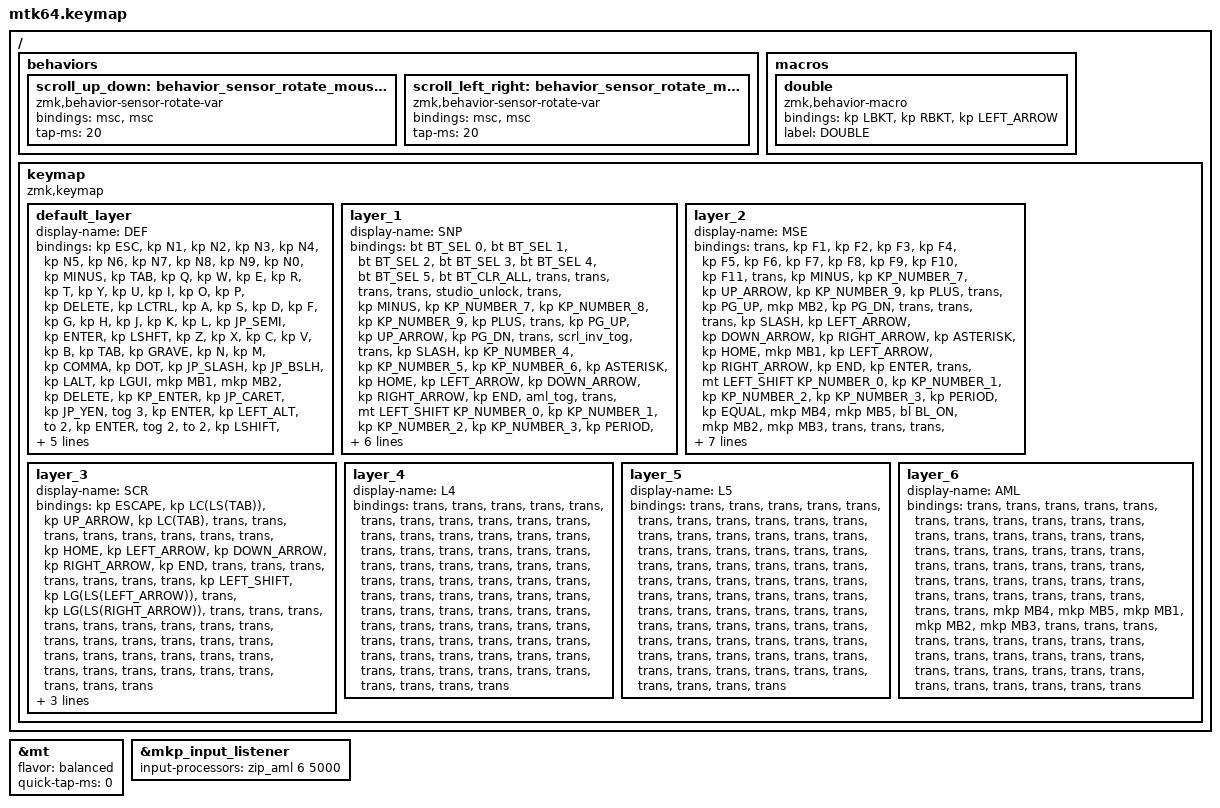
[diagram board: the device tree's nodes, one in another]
#include <input/processors.dtsi>
#include <behaviors.dtsi>
#include <dt-bindings/zmk/backlight.h>
#include <dt-bindings/zmk/bt.h>
#include <dt-bindings/zmk/keys.h>
#include <dt-bindings/zmk/pointing.h>
#include "keycode_japanese.h"

// スクロール量の設定

#define ZMK_POINTING_DEFAULT_SCRL_VAL 100

&mt {
    flavor = "balanced";
    quick-tap-ms = <0>;
};

&mkp_input_listener { input-processors = <&zip_aml 6 5000>; };

/ {
    behaviors {
        // 垂直スクロール用のbehaviorの設定

        scroll_up_down: behavior_sensor_rotate_mouse_wheel_up_down {
            compatible = "zmk,behavior-sensor-rotate-var";
            #sensor-binding-cells = <2>;
            bindings = <&msc>, <&msc>;

            tap-ms = <20>; // スクロールのタップ時間
        };

        // 水平スクロール用のbehaviorの設定

        scroll_left_right: behavior_sensor_rotate_mouse_wheel_left_right {
            compatible = "zmk,behavior-sensor-rotate-var";
            #sensor-binding-cells = <2>;
            bindings = <&msc>, <&msc>;

            tap-ms = <20>; // スクロールのタップ時間
        };
    };
};

/ {
    macros {
        double: double {
            compatible = "zmk,behavior-macro";
            #binding-cells = <0>;
            bindings = <&kp LBKT &kp RBKT &kp LEFT_ARROW>;
            label = "DOUBLE";
        };
    };

    keymap {
        compatible = "zmk,keymap";

        default_layer {
            display-name = "DEF";
            bindings = <
&kp ESC  &kp N1  &kp N2  &kp N3  &kp N4  &kp N5  &kp N6  &kp N7  &kp N8  &kp N9  &kp N0  &kp MINUS  &kp TAB  &kp Q  &kp W  &kp E  &kp R  &kp T  &kp Y  &kp U  &kp I  &kp O  &kp P  &kp DELETE  &kp LCTRL  &kp A  &kp S  &kp D  &kp F  &kp G  &kp H  &kp J  &kp K  &kp L  &kp JP_SEMI  &kp ENTER  &kp LSHFT  &kp Z  &kp X  &kp C  &kp V  &kp B  &kp TAB  &kp GRAVE  &kp N  &kp M  &kp COMMA  &kp DOT  &kp JP_SLASH  &kp JP_BSLH  &kp LALT  &kp LGUI  &mkp MB1  &mkp MB2  &kp DELETE  &kp KP_ENTER  &kp JP_CARET  &kp JP_YEN  &tog 3  &kp ENTER  &kp LEFT_ALT  &to 2  &kp ENTER  &tog 2  &to 2  &kp LSHIFT  &mo 1  &mo 2  &mo 3  &mo 1  &mo 2  &mo 3  &mo 1  &mo 2  &mo 3
            >;

            sensor-bindings = <
                &inc_dec_kp LEFT_ARROW RIGHT_ARROW
                &inc_dec_kp UP_ARROW   DOWN_ARROW
            >;
        };

        layer_1 {
            display-name = "SNP";
            bindings = <
&bt BT_SEL 0  &bt BT_SEL 1  &bt BT_SEL 2  &bt BT_SEL 3  &bt BT_SEL 4  &bt BT_SEL 5  &bt BT_CLR_ALL  &trans  &trans  &trans  &trans  &studio_unlock  &trans  &kp MINUS  &kp KP_NUMBER_7  &kp KP_NUMBER_8  &kp KP_NUMBER_9  &kp PLUS  &trans  &kp PG_UP  &kp UP_ARROW  &kp PG_DN  &trans  &scrl_inv_tog  &trans  &kp SLASH  &kp KP_NUMBER_4  &kp KP_NUMBER_5  &kp KP_NUMBER_6  &kp ASTERISK  &kp HOME  &kp LEFT_ARROW  &kp DOWN_ARROW  &kp RIGHT_ARROW  &kp END  &aml_tog  &trans  &mt LEFT_SHIFT KP_NUMBER_0  &kp KP_NUMBER_1  &kp KP_NUMBER_2  &kp KP_NUMBER_3  &kp PERIOD  &kp EQUAL  &mkp MB4  &mkp MB5  &bl BL_OFF  &mkp MB2  &mkp MB3  &trans  &cpi_inc  &trans  &trans  &trans  &trans  &trans  &trans  &trans  &cpi_dec  &trans  &trans  &trans  &trans  &trans  &trans  &trans  &trans  &trans  &trans  &trans  &trans  &trans  &trans  &trans  &trans  &trans
            >;
        };

        layer_2 {
            display-name = "MSE";
            bindings = <
&trans  &kp F1  &kp F2  &kp F3  &kp F4  &kp F5  &kp F6  &kp F7  &kp F8  &kp F9  &kp F10  &kp F11  &trans  &kp MINUS  &kp KP_NUMBER_7  &kp UP_ARROW  &kp KP_NUMBER_9  &kp PLUS  &trans  &kp PG_UP  &mkp MB2  &kp PG_DN  &trans  &trans  &trans  &kp SLASH  &kp LEFT_ARROW  &kp DOWN_ARROW  &kp RIGHT_ARROW  &kp ASTERISK  &kp HOME  &mkp MB1  &kp LEFT_ARROW  &kp RIGHT_ARROW  &kp END  &kp ENTER  &trans  &mt LEFT_SHIFT KP_NUMBER_0  &kp KP_NUMBER_1  &kp KP_NUMBER_2  &kp KP_NUMBER_3  &kp PERIOD  &kp EQUAL  &mkp MB4  &mkp MB5  &bl BL_ON  &mkp MB2  &mkp MB3  &trans  &trans  &trans  &trans  &trans  &trans  &mkp MB2  &mkp MB1  &trans  &trans  &trans  &trans  &trans  &to 0  &trans  &trans  &to 0  &trans  &trans  &trans  &trans  &trans  &trans  &trans  &trans  &trans  &trans
            >;

            sensor-bindings = <
                &inc_dec_kp TAB LS(TAB) 
                &inc_dec_kp PG_UP PG_DN
            >;
        };

        layer_3 {
            display-name = "SCR";
            bindings = <
&kp ESCAPE  &kp LC(LS(TAB))  &kp UP_ARROW  &kp LC(TAB)  &trans  &trans  &trans  &trans  &trans  &trans  &trans  &trans  &kp HOME  &kp LEFT_ARROW  &kp DOWN_ARROW  &kp RIGHT_ARROW  &kp END  &trans  &trans  &trans  &trans  &trans  &trans  &trans  &kp LEFT_SHIFT  &kp LG(LS(LEFT_ARROW))  &trans  &kp LG(LS(RIGHT_ARROW))  &trans  &trans  &trans  &trans  &trans  &trans  &trans  &trans  &trans  &trans  &trans  &trans  &trans  &trans  &trans  &trans  &trans  &trans  &trans  &trans  &trans  &trans  &trans  &trans  &trans  &trans  &trans  &trans  &trans  &trans
            >;

            sensor-bindings = <
                &scroll_left_right SCRL_LEFT SCRL_RIGHT
                &scroll_up_down SCRL_UP SCRL_DOWN
            >;
        };

        layer_4 {
            display-name = "L4";
            bindings = <
&trans  &trans  &trans  &trans  &trans  &trans  &trans  &trans  &trans  &trans  &trans  &trans  &trans  &trans  &trans  &trans  &trans  &trans  &trans  &trans  &trans  &trans  &trans  &trans  &trans  &trans  &trans  &trans  &trans  &trans  &trans  &trans  &trans  &trans  &trans  &trans  &trans  &trans  &trans  &trans  &trans  &trans  &trans  &trans  &trans  &trans  &trans  &trans  &trans  &trans  &trans  &trans  &trans  &trans  &trans  &trans  &trans  &trans  &trans  &trans  &trans  &trans  &trans  &trans  &trans  &trans  &trans  &trans  &trans  &trans  &trans  &trans  &trans  &trans  &trans
            >;
        };

        layer_5 {
            display-name = "L5";
            bindings = <
&trans  &trans  &trans  &trans  &trans  &trans  &trans  &trans  &trans  &trans  &trans  &trans  &trans  &trans  &trans  &trans  &trans  &trans  &trans  &trans  &trans  &trans  &trans  &trans  &trans  &trans  &trans  &trans  &trans  &trans  &trans  &trans  &trans  &trans  &trans  &trans  &trans  &trans  &trans  &trans  &trans  &trans  &trans  &trans  &trans  &trans  &trans  &trans  &trans  &trans  &trans  &trans  &trans  &trans  &trans  &trans  &trans  &trans  &trans  &trans  &trans  &trans  &trans  &trans  &trans  &trans  &trans  &trans  &trans  &trans  &trans  &trans  &trans  &trans  &trans
            >;
        };

        layer_6 {
            display-name = "AML";
            bindings = <
&trans  &trans  &trans  &trans  &trans  &trans  &trans  &trans  &trans  &trans  &trans  &trans  &trans  &trans  &trans  &trans  &trans  &trans  &trans  &trans  &trans  &trans  &trans  &trans  &trans  &trans  &trans  &trans  &trans  &trans  &trans  &trans  &trans  &trans  &trans  &trans  &trans  &trans  &trans  &trans  &trans  &trans  &trans  &mkp MB4  &mkp MB5  &mkp MB1  &mkp MB2  &mkp MB3  &trans  &trans  &trans  &trans  &trans  &trans  &trans  &trans  &trans  &trans  &trans  &trans  &trans  &trans  &trans  &trans  &trans  &trans  &trans  &trans  &trans  &trans  &trans  &trans  &trans  &trans  &trans
            >;
        };
    };
};
